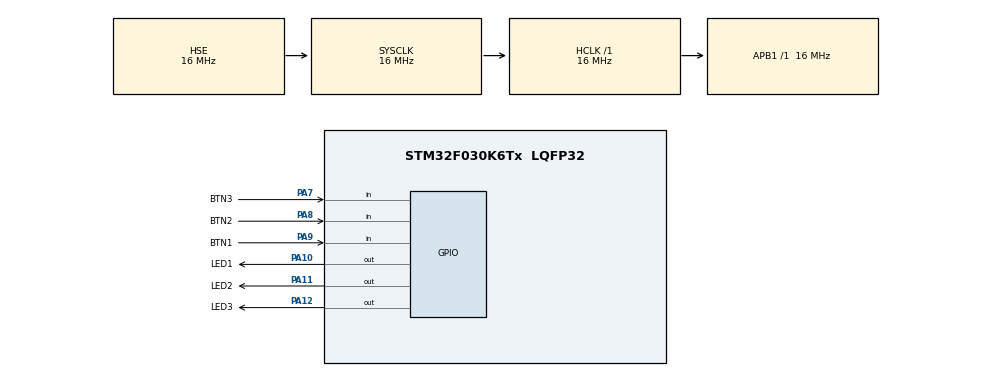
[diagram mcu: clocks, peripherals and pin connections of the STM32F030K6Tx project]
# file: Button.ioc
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Mcu.Family=STM32F0
Mcu.Name=STM32F030K6Tx
Mcu.Package=LQFP32
PA10.GPIO_Label=LED1
PA10.Signal=GPIO_Output
PA11.GPIO_Label=LED2
PA11.Signal=GPIO_Output
PA12.GPIO_Label=LED3
PA12.Signal=GPIO_Output
PA13.Mode=Serial_Wire
PA13.Signal=SYS_SWDIO
PA14.Mode=Serial_Wire
PA14.Signal=SYS_SWCLK
PA7.GPIO_Label=BTN3
PA7.GPIO_PuPd=GPIO_PULLUP
PA7.Signal=GPIO_Input
PA8.GPIO_Label=BTN2
PA8.GPIO_PuPd=GPIO_PULLUP
PA8.Signal=GPIO_Input
PA9.GPIO_Label=BTN1
PA9.GPIO_PuPd=GPIO_PULLUP
PA9.Signal=GPIO_Input
PF0-OSC_IN.Mode=HSE-External-Oscillator
PF0-OSC_IN.Signal=RCC_OSC_IN
PF1-OSC_OUT.Mode=HSE-External-Oscillator
PF1-OSC_OUT.Signal=RCC_OSC_OUT
ProjectManager.HeapSize=0x200
ProjectManager.StackSize=0x400
ProjectManager.TargetToolchain=STM32CubeIDE
RCC.AHBFreq_Value=16000000
RCC.APB1Freq_Value=16000000
RCC.APB1TimFreq_Value=16000000
RCC.HCLKFreq_Value=16000000
RCC.HSE_VALUE=16000000
RCC.PLLSourceVirtual=RCC_PLLSOURCE_HSE
RCC.SYSCLKFreq_VALUE=16000000
RCC.SYSCLKSource=RCC_SYSCLKSOURCE_HSE
board=custom

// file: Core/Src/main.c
/* USER CODE BEGIN Header */
/**
  ******************************************************************************
  * @file           : main.c
  * @brief          : Main program body
  ******************************************************************************
  * @attention
  *
  * Copyright (c) 2022 STMicroelectronics.
  * All rights reserved.
  *
  * This software is licensed under terms that can be found in the LICENSE file
  * in the root directory of this software component.
  * If no LICENSE file comes with this software, it is provided AS-IS.
  *
  ******************************************************************************
  */
/* USER CODE END Header */
#include "main.h"

void SystemClock_Config(void);
static void MX_GPIO_Init(void);

int main(void)
{

  /* MCU Configuration--------------------------------------------------------*/

  /* Reset of all peripherals, Initializes the Flash interface and the Systick. */
  HAL_Init();

  /* Configure the system clock */
  SystemClock_Config();

  /* Initialize all configured peripherals */
  MX_GPIO_Init();

  /* Infinite loop */
  while (1)
  {

    /* USER CODE BEGIN 3 */

	if(!HAL_GPIO_ReadPin(GPIOA, BTN1_Pin))
	{
		HAL_GPIO_WritePin(GPIOA, LED1_Pin, GPIO_PIN_SET);
	}
	else
	{
		HAL_GPIO_WritePin(GPIOA, LED1_Pin, GPIO_PIN_RESET);
	}

	if(!HAL_GPIO_ReadPin(GPIOA, BTN2_Pin))
	{
		HAL_GPIO_WritePin(GPIOA, LED2_Pin, GPIO_PIN_SET);
	}
	else
	{
		HAL_GPIO_WritePin(GPIOA, LED2_Pin, GPIO_PIN_RESET);
	}

	if(!HAL_GPIO_ReadPin(GPIOA, BTN3_Pin))
	{
		HAL_GPIO_WritePin(GPIOA, LED3_Pin, GPIO_PIN_SET);
	}
	else
	{
		HAL_GPIO_WritePin(GPIOA, LED3_Pin, GPIO_PIN_RESET);
	}
  }
  /* USER CODE END 3 */
}

void SystemClock_Config(void)
{
  RCC_OscInitTypeDef RCC_OscInitStruct = {0};
  RCC_ClkInitTypeDef RCC_ClkInitStruct = {0};

  /** Initializes the RCC Oscillators according to the specified parameters
  * in the RCC_OscInitTypeDef structure.
  */
  RCC_OscInitStruct.OscillatorType = RCC_OSCILLATORTYPE_HSE;
  RCC_OscInitStruct.HSEState = RCC_HSE_ON;
  RCC_OscInitStruct.PLL.PLLState = RCC_PLL_NONE;
  if (HAL_RCC_OscConfig(&RCC_OscInitStruct) != HAL_OK)
  {
    Error_Handler();
  }

  /** Initializes the CPU, AHB and APB buses clocks
  */
  RCC_ClkInitStruct.ClockType = RCC_CLOCKTYPE_HCLK|RCC_CLOCKTYPE_SYSCLK
                              |RCC_CLOCKTYPE_PCLK1;
  RCC_ClkInitStruct.SYSCLKSource = RCC_SYSCLKSOURCE_HSE;
  RCC_ClkInitStruct.AHBCLKDivider = RCC_SYSCLK_DIV1;
  RCC_ClkInitStruct.APB1CLKDivider = RCC_HCLK_DIV1;

  if (HAL_RCC_ClockConfig(&RCC_ClkInitStruct, FLASH_LATENCY_0) != HAL_OK)
  {
    Error_Handler();
  }
}

static void MX_GPIO_Init(void)
{
  GPIO_InitTypeDef GPIO_InitStruct = {0};

  /* GPIO Ports Clock Enable */
  __HAL_RCC_GPIOF_CLK_ENABLE();
  __HAL_RCC_GPIOA_CLK_ENABLE();

  /*Configure GPIO pin Output Level */
  HAL_GPIO_WritePin(GPIOA, LED1_Pin|LED2_Pin|LED3_Pin, GPIO_PIN_RESET);

  /*Configure GPIO pins : BTN3_Pin BTN2_Pin BTN1_Pin */
  GPIO_InitStruct.Pin = BTN3_Pin|BTN2_Pin|BTN1_Pin;
  GPIO_InitStruct.Mode = GPIO_MODE_INPUT;
  GPIO_InitStruct.Pull = GPIO_PULLUP;
  HAL_GPIO_Init(GPIOA, &GPIO_InitStruct);

  /*Configure GPIO pins : LED1_Pin LED2_Pin LED3_Pin */
  GPIO_InitStruct.Pin = LED1_Pin|LED2_Pin|LED3_Pin;
  GPIO_InitStruct.Mode = GPIO_MODE_OUTPUT_PP;
  GPIO_InitStruct.Pull = GPIO_NOPULL;
  GPIO_InitStruct.Speed = GPIO_SPEED_FREQ_LOW;
  HAL_GPIO_Init(GPIOA, &GPIO_InitStruct);

}

void Error_Handler(void)
{
  __disable_irq();
  while (1)
  {
  }
}
